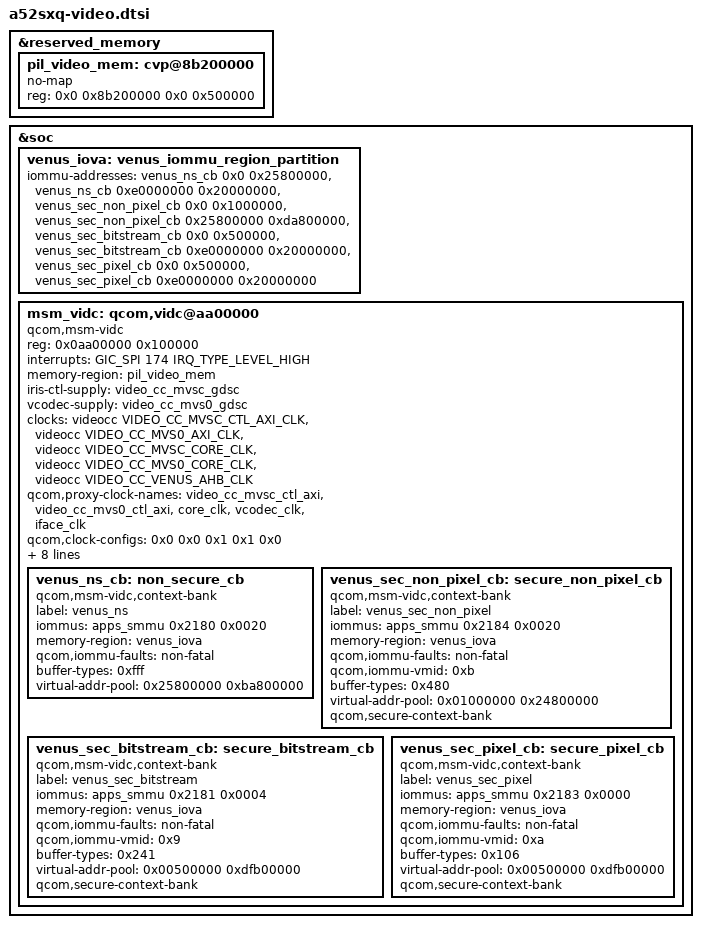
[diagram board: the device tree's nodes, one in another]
// SPDX-License-Identifier: GPL-2.0-only
/*
 * a52sxq video codec (Venus/iris2) for the forward-ported 5.4 msm_vidc
 * (drivers612/gpu-video/video, msm-vidc.ko) on the Qualcomm 6.12 base
 * (bsp612/out/dist/dtb/yupik.dtb, downstream bindings).
 *
 * Source of every value: the tree the phone boots, downstream-dt/a52sxq-r02.dts
 * node /soc/qcom,vidc (line 19233), which is Qualcomm's yupik-vidc.dtsi
 * unchanged: the Samsung dts sources (arch/arm64/boot/dts/samsung/) do not
 * touch the video node, so hardware revisions 3 and 4 are identical here.
 * No GPIO, no PMIC rail: the two supplies are the videocc GDSCs.
 *
 * The 6.12 base has NO video node for yupik at all (no msm-vidc, no iris/v2
 * "qcom,sm*-vidc" node, no venus PIL node): nothing has to be disabled. It
 * only has videocc (qcom,sc7280-videocc), both GDSCs and an unused
 * reserved region `video_mem` (0x85b00000). If a later base adds a v2 node
 * (compatible "qcom,msm-vidc" on the same reg, or "qcom,sc7280-venus"/iris),
 * it must be status = "disabled": both would claim 0xaa00000 and IRQ 174.
 *
 * Differences from the 5.4 node, all forced by 6.12:
 *  - memory-region: 5.4 loaded the firmware through the PIL node
 *    qcom,venus@aab0000 (pas-id 9, memory-region = pil_video_mem). 6.12 has
 *    no PIL; the driver loads <vidc,firmware-name>.mdt with the MDT loader
 *    and SCM PAS id 9 into the region named here (vidc_612.c).
 *  - qcom,iommu-dma-addr-pool is not used by the 6.12 base (0 users in
 *    yupik.dtb); the IOVA window of each context bank is given the 6.12 way,
 *    by reserving everything outside it with iommu-addresses. The driver
 *    still reads virtual-addr-pool.
 *  - dma-coherent-hint-cached: no 6.12 code reads it; dropped.
 */

#include <dt-bindings/clock/qcom,videocc-sc7280.h>	/* same numbers as 5.4 qcom,videocc-yupik.h (checked) */
#include <dt-bindings/interconnect/qcom,yupik.h>	/* same ids as 5.4 (checked) */
#include <dt-bindings/interrupt-controller/arm-gic.h>

&reserved_memory {
	/*
	 * Venus firmware, where the phone's 5.4 map has it (5.4 label
	 * pil_video_mem, node name cvp@8b200000, 5 MiB). The 6.12 base leaves
	 * 0x8b200000..0x8b6fffff unreserved (pil_camera_mem ends at 0x8b200000,
	 * pil_ipa_fw_mem starts at 0x8b700000). If the a52sxq memory-map
	 * fragment already defines this node, delete it here.
	 */
	pil_video_mem: cvp@8b200000 {
		no-map;
		reg = <0x0 0x8b200000 0x0 0x500000>;
	};
};

&soc {
	/* everything outside the 5.4 qcom,iommu-dma-addr-pool of each bank */
	venus_iova: venus_iommu_region_partition {
		iommu-addresses = <&venus_ns_cb 0x0 0x25800000>,
				  <&venus_ns_cb 0xe0000000 0x20000000>,
				  <&venus_sec_non_pixel_cb 0x0 0x1000000>,
				  <&venus_sec_non_pixel_cb 0x25800000 0xda800000>,
				  <&venus_sec_bitstream_cb 0x0 0x500000>,
				  <&venus_sec_bitstream_cb 0xe0000000 0x20000000>,
				  <&venus_sec_pixel_cb 0x0 0x500000>,
				  <&venus_sec_pixel_cb 0xe0000000 0x20000000>;
	};

	msm_vidc: qcom,vidc@aa00000 {
		compatible = "qcom,msm-vidc", "qcom,yupik-vidc";
		status = "okay";
		reg = <0x0aa00000 0x100000>;
		interrupts = <GIC_SPI 174 IRQ_TYPE_LEVEL_HIGH>;
		memory-region = <&pil_video_mem>;

		#address-cells = <1>;
		#size-cells = <1>;

		iris-ctl-supply = <&video_cc_mvsc_gdsc>;
		vcodec-supply = <&video_cc_mvs0_gdsc>;

		clock-names = "video_cc_mvsc_ctl_axi", "video_cc_mvs0_ctl_axi",
			      "core_clk", "vcodec_clk", "iface_clk";
		clocks = <&videocc VIDEO_CC_MVSC_CTL_AXI_CLK>,
			 <&videocc VIDEO_CC_MVS0_AXI_CLK>,
			 <&videocc VIDEO_CC_MVSC_CORE_CLK>,
			 <&videocc VIDEO_CC_MVS0_CORE_CLK>,
			 <&videocc VIDEO_CC_VENUS_AHB_CLK>;
		qcom,proxy-clock-names = "video_cc_mvsc_ctl_axi",
					 "video_cc_mvs0_ctl_axi", "core_clk",
					 "vcodec_clk", "iface_clk";
		/* bit0: clock scaling, bit1: memory retention */
		qcom,clock-configs = <0x0 0x0 0x1 0x1 0x0>;
		qcom,allowed-clock-rates = <133330000 240000000 335000000
					    424000000 460000000>;

		qcom,reg-presets = <0xb0088 0x0 0x11>;

		/* /vendor/firmware_mnt/image/vpu20_1v.{mdt,b00..b10,b19} */
		vidc,firmware-name = "vpu20_1v";

		interconnect-names = "venus-cnoc", "venus-ddr";
		interconnects = <&gem_noc MASTER_APPSS_PROC &cnoc2 SLAVE_VENUS_CFG>,
				<&mmss_noc MASTER_VIDEO_P0 &mc_virt SLAVE_EBI1>;
		/* (low, high) kbps per bus */
		qcom,bus-range-kbps = <1000 1000>, <1000 8000000>;

		venus_ns_cb: non_secure_cb {
			compatible = "qcom,msm-vidc,context-bank";
			label = "venus_ns";
			iommus = <&apps_smmu 0x2180 0x0020>;
			memory-region = <&venus_iova>;
			qcom,iommu-faults = "non-fatal";
			buffer-types = <0xfff>;
			virtual-addr-pool = <0x25800000 0xba800000>;
		};

		venus_sec_non_pixel_cb: secure_non_pixel_cb {
			compatible = "qcom,msm-vidc,context-bank";
			label = "venus_sec_non_pixel";
			iommus = <&apps_smmu 0x2184 0x0020>;
			memory-region = <&venus_iova>;
			qcom,iommu-faults = "non-fatal";
			qcom,iommu-vmid = <0xb>;	/* VMID_CP_NON_PIXEL */
			buffer-types = <0x480>;
			virtual-addr-pool = <0x01000000 0x24800000>;
			qcom,secure-context-bank;
		};

		venus_sec_bitstream_cb: secure_bitstream_cb {
			compatible = "qcom,msm-vidc,context-bank";
			label = "venus_sec_bitstream";
			iommus = <&apps_smmu 0x2181 0x0004>;
			memory-region = <&venus_iova>;
			qcom,iommu-faults = "non-fatal";
			qcom,iommu-vmid = <0x9>;	/* VMID_CP_BITSTREAM */
			buffer-types = <0x241>;
			virtual-addr-pool = <0x00500000 0xdfb00000>;
			qcom,secure-context-bank;
		};

		venus_sec_pixel_cb: secure_pixel_cb {
			compatible = "qcom,msm-vidc,context-bank";
			label = "venus_sec_pixel";
			iommus = <&apps_smmu 0x2183 0x0000>;
			memory-region = <&venus_iova>;
			qcom,iommu-faults = "non-fatal";
			qcom,iommu-vmid = <0xa>;	/* VMID_CP_PIXEL */
			buffer-types = <0x106>;
			virtual-addr-pool = <0x00500000 0xdfb00000>;
			qcom,secure-context-bank;
		};
	};
};
